# CEC1702 register map
Vendor: Microchip
Registers are 32-bit, read-write, reset 0x0 unless marked. A register's access mark holds for its fields unless they carry their own. Addresses are absolute, and some are shared; only a register's first bit layout is shown; [hi:lo] are bit positions.

## RC_ID1
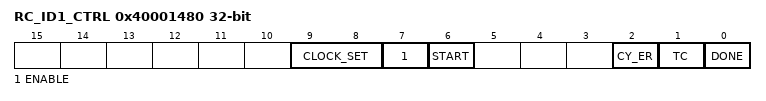
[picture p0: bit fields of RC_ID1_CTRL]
0x40001480 RC_ID1_CTRL
  [9:8] CLOCK_SET — This field selects the frequency of the Counter circuit clock. This field must retain the same value as long as the ENABLE bit in this register is 1.
  [7] ENABLE — Clearing the bit to 0 causes the RC_ID interface to enter the Reset state, gating its clocks, clearing the status bits in this register and entering into its lowest power state. Setting this bit to 1 causes the RC_ID interface to enter the Armed phase of an RC_ID measurement.
  [6] START — Setting this bit to 1 initiates the Discharged phase of an RC_ID measurement.
  [2] CY_ER — This bit is 1 if an RC_ID measurement encountered an error and the reading in the RC_ID Data Register is invalid. This bit is cleared to 0 when the RC_ID interface is in the Reset phase.
  [1] TC — This bit is cleared to 0 when the RC_ID interface is in the Reset phase, and set to 1 when the interface completes the Discharged phase of an RC_ID measurement.
  [0] DONE — This bit is cleared to 0 when the RC_ID interface is in the Reset phase, and set to 1 when the interface completes an RC_ID measurement.
0x40001484 RC_ID1_DAT
  [15:0] RCID_DATA — Reads of this register provide the result of an RC_ID measurement.

## DMA_MAIN
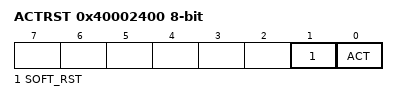
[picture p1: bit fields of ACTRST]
0x40002400 ACTRST 8-bit
  [1] SOFT_RST — Soft reset the entire module. This bit is self-clearing.
  [0] ACT — Enable the blocks operation. (R/WS). 1=Enable block. Each individual channel must be enabled separately. 0=Disable all channels.
0x40002404 DATA_PKT ro

## PWM0
0x40005800 CNT_ON
0x40005804 CNT_OFF
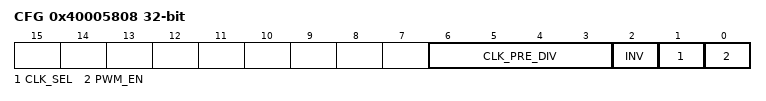
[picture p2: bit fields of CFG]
0x40005808 CFG
  [6:3] CLK_PRE_DIV — The Clock source for the 16-bit down counter (see PWMx Counter ON Time Register and PWMx Counter OFF Time Register) is determined by bit D1 of this register. The Clock source is then divided by the value of Pre-Divider+1 and the resulting signal determines the rate at which the down counter will be decremented. For example, a Pre-Divider value of 1 divides the input clock by 2 and a value of 2 divides the input clock by 3. A Pre-Divider of 0 will disable the Pre-Divider option.
  [2] INV — 1= PWM_OUTPUT ON State is active low; 0=PWM_OUTPUT ON State is active high.
  [1] CLK_SEL — This bit determines the clock source used by the PWM duty cycle and frequency control logic. 1=CLOCK_LOW. 0=CLOCK_HIGH
  [0] PWM_EN — When the PWM_EN is set to 0 the internal counters are reset and the internal state machine is set to the OFF state. In addition, the PWM_OUTPUT signal is set to the inactive state as determined by the Invert bit. The PWMx Counter ON Time Register and PWMx Counter OFF Time Register are not affected by the PWM_ENABLE bit and may be read and written while the PWM enable bit is 0. 1=Enabled (default); 0=Disabled (gates clocks to save power).

## PWM1
0x40005810 CNT_ON
0x40005814 CNT_OFF
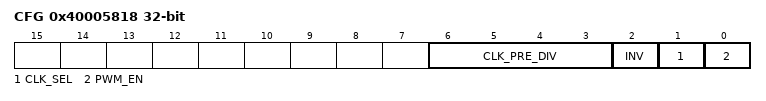
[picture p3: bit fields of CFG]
0x40005818 CFG
  [6:3] CLK_PRE_DIV — The Clock source for the 16-bit down counter (see PWMx Counter ON Time Register and PWMx Counter OFF Time Register) is determined by bit D1 of this register. The Clock source is then divided by the value of Pre-Divider+1 and the resulting signal determines the rate at which the down counter will be decremented. For example, a Pre-Divider value of 1 divides the input clock by 2 and a value of 2 divides the input clock by 3. A Pre-Divider of 0 will disable the Pre-Divider option.
  [2] INV — 1= PWM_OUTPUT ON State is active low; 0=PWM_OUTPUT ON State is active high.
  [1] CLK_SEL — This bit determines the clock source used by the PWM duty cycle and frequency control logic. 1=CLOCK_LOW. 0=CLOCK_HIGH
  [0] PWM_EN — When the PWM_EN is set to 0 the internal counters are reset and the internal state machine is set to the OFF state. In addition, the PWM_OUTPUT signal is set to the inactive state as determined by the Invert bit. The PWMx Counter ON Time Register and PWMx Counter OFF Time Register are not affected by the PWM_ENABLE bit and may be read and written while the PWM enable bit is 0. 1=Enabled (default); 0=Disabled (gates clocks to save power).
